# STM32H5F4 register map
File version: 1.0
CPU: CM33 r0p0, little endian, MPU, FPU, 4 interrupt priority bits
Registers are 32-bit, read-write, reset 0x0 unless marked. A register's access mark holds for its fields unless they carry their own. Offsets are from the block's base; [hi:lo] are bit positions; {n}, {i} and the like mark numbered series.

## CEC — CEC address block description
Base 0x40007000
Same registers: CEC_S 0x50007000
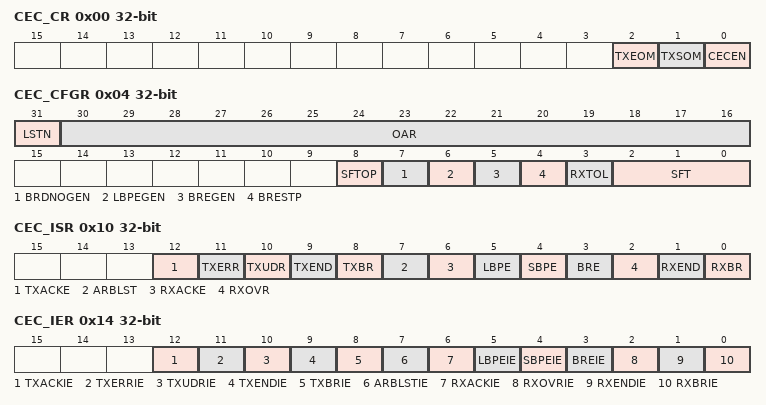
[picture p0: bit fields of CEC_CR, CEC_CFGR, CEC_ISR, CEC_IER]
0x00 CEC_CR — CEC control register
  [2] TXEOM — Tx end of message
    0=TXDR data byte is transmitted with EOM=0; 1=TXDR data byte is transmitted with EOM=1
  [1] TXSOM — Tx start of message
    0=No CEC transmission is on-going; 1=CEC transmission command
  [0] CECEN — CEC enable
    0=CEC peripheral is off; 1=CEC peripheral is on
0x04 CEC_CFGR — CEC configuration register
  [31] LSTN — Listen mode
    0=CEC peripheral receives only message addressed to its own address (OAR); 1=CEC peripheral receives messages addressed to its own address (OAR) with positive acknowledge
  [30:16] OAR — Own addresses configuration
  [8] SFTOP — SFT option bit
    0=SFT timer starts when TXSOM is set by software; 1=SFT timer starts automatically at the end of message transmission/reception
  [7] BRDNOGEN — Avoid error-bit generation in broadcast
    0=BRE detection with BRESTP=1 and BREGEN=0 on a broadcast message generates an; 1=Error-bit is not generated in the same condition as above
  [6] LBPEGEN — Generate error-bit on long bit period error
    0=LBPE detection does not generate an error-bit on the CEC line; 1=LBPE detection generates an error-bit on the CEC line
  [5] BREGEN — Generate error-bit on bit rising error
    0=BRE detection does not generate an error-bit on the CEC line; 1=BRE detection generates an error-bit on the CEC line (if BRESTP is set)
  [4] BRESTP — Rx-stop on bit rising error
    0=BRE detection does not stop reception of the CEC message; 1=BRE detection stops message reception
  [3] RXTOL — Rx-tolerance
    0=Standard tolerance margin:; 1=Extended tolerance
  [2:0] SFT — Signal free time
    {v}={v-1} (v=1..7)
0x08 CEC_TXDR wo — CEC Tx data register
  [7:0] TXD — Tx data
0x0C CEC_RXDR ro — CEC Rx data register
  [7:0] RXD — Rx data
0x10 CEC_ISR — CEC interrupt and status register
  [12] TXACKE — Tx-missing acknowledge error
  [11] TXERR — Tx-error
  [10] TXUDR — Tx-buffer underrun
  [9] TXEND — End of transmission
  [8] TXBR — Tx-byte request
  [7] ARBLST — Arbitration lost
  [6] RXACKE — Rx-missing acknowledge
  [5] LBPE — Rx-long bit period error
  [4] SBPE — Rx-short bit period error
  [3] BRE — Rx-bit rising error
  [2] RXOVR — Rx-overrun
  [1] RXEND — End of reception
  [0] RXBR — Rx-byte received
0x14 CEC_IER — CEC interrupt enable register
  [12] TXACKIE — Tx-missing acknowledge error interrupt enable
    0=TXACKE interrupt disabled; 1=TXACKE interrupt enabled
  [11] TXERRIE — Tx-error interrupt enable
    0=TXERR interrupt disabled; 1=TXERR interrupt enabled
  [10] TXUDRIE — Tx-underrun interrupt enable
    0=TXUDR interrupt disabled; 1=TXUDR interrupt enabled
  [9] TXENDIE — Tx-end of message interrupt enable
    0=TXEND interrupt disabled; 1=TXEND interrupt enabled
  [8] TXBRIE — Tx-byte request interrupt enable
    0=TXBR interrupt disabled; 1=TXBR interrupt enabled
  [7] ARBLSTIE — Arbitration lost interrupt enable
    0=ARBLST interrupt disabled; 1=ARBLST interrupt enabled
  [6] RXACKIE — Rx-missing acknowledge error interrupt enable
    0=RXACKE interrupt disabled; 1=RXACKE interrupt enabled
  [5] LBPEIE — Long bit period error interrupt enable
    0=LBPE interrupt disabled; 1=LBPE interrupt enabled
  [4] SBPEIE — Short bit period error interrupt enable
    0=SBPE interrupt disabled; 1=SBPE interrupt enabled
  [3] BREIE — Bit rising error interrupt enable
    0=BRE interrupt disabled; 1=BRE interrupt enabled
  [2] RXOVRIE — Rx-buffer overrun interrupt enable
    0=RXOVR interrupt disabled; 1=RXOVR interrupt enabled
  [1] RXENDIE — End of reception interrupt enable
    0=RXEND interrupt disabled; 1=RXEND interrupt enabled
  [0] RXBRIE — Rx-byte received interrupt enable
    0=RXBR interrupt disabled; 1=RXBR interrupt enabled

## Notices in the file
Copyright (c) 2025 STMicroelectronics.
SPDX-License-Identifier: Apache-2.0
Licensed under the Apache License, Version 2.0 (the "License");
you may not use this file except in compliance with the License.
You may obtain a copy of the License at
http://www.apache.org/licenses/LICENSE-2.0
Unless required by applicable law or agreed to in writing, software
distributed under the License is distributed on an "AS IS" BASIS,
WITHOUT WARRANTIES OR CONDITIONS OF ANY KIND, either express or implied.
See the License for the specific language governing permissions and
limitations under the License.
